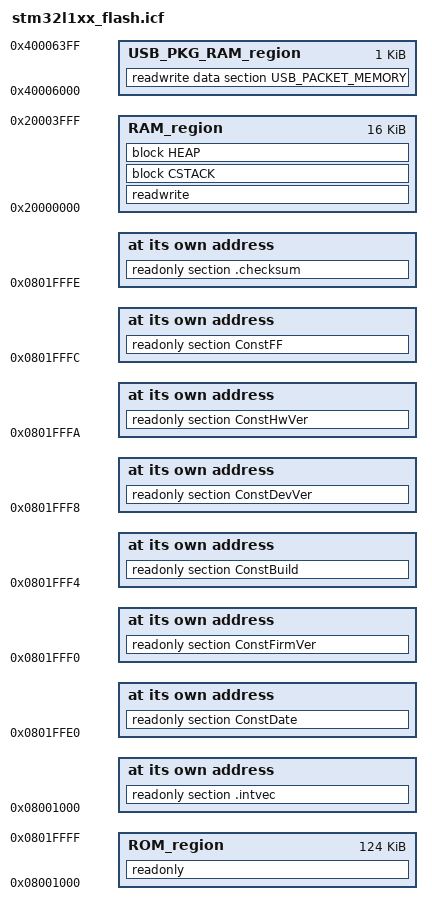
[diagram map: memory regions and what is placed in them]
/*###ICF### Section handled by ICF editor, don't touch! ****/
/*-Editor annotation file-*/
/* IcfEditorFile="$TOOLKIT_DIR$\config\ide\IcfEditor\cortex_v1_0.xml" */
/*-Specials-*/
define symbol __ICFEDIT_intvec_start__ = 0x08001000;
define symbol CHECKSUM                 = 0x0801FFFE;
define symbol __CONST_DATE             = 0x0801FFE0;
define symbol __CONST_FIRM_VER         = 0x0801FFF0;
define symbol __CONST_BUILD            = 0x0801FFF4;
define symbol __CONST_DEV_VER          = 0x0801FFF8;
define symbol __CONST_HW_VER           = 0x0801FFFA;
define symbol __CONST_FF               = 0x0801FFFC;

/*-Memory Regions-*/
define symbol __ICFEDIT_region_ROM_start__ = 0x08001000;
define symbol __ICFEDIT_region_ROM_end__   = 0x0801FFFF;
define symbol __ICFEDIT_region_RAM_start__ = 0x20000000;
define symbol __ICFEDIT_region_RAM_end__   = 0x20003FFF;
/*-Sizes-*/
define symbol __ICFEDIT_size_cstack__ = 0x250;
define symbol __ICFEDIT_size_heap__   = 0x0;
/**** End of ICF editor section. ###ICF###*/

define memory mem with size = 4G;
define region ROM_region   = mem:[from __ICFEDIT_region_ROM_start__   to __ICFEDIT_region_ROM_end__];
define region RAM_region   = mem:[from __ICFEDIT_region_RAM_start__   to __ICFEDIT_region_RAM_end__];

define symbol __region_USB_PKG_RAM_start__  = 0x40006000;
define symbol __region_USB_PKG_RAM_end__    = 0x400063FF;
define region USB_PKG_RAM_region = mem:[from __region_USB_PKG_RAM_start__ to __region_USB_PKG_RAM_end__];

define block CSTACK    with alignment = 8, size = __ICFEDIT_size_cstack__   { };
define block HEAP      with alignment = 8, size = __ICFEDIT_size_heap__     { };

initialize by copy { readwrite };
do not initialize  { section .noinit };

place at address mem:__ICFEDIT_intvec_start__ { readonly section .intvec };
place at address mem: CHECKSUM   { readonly section .checksum };
place at address mem: __CONST_DATE   { readonly section ConstDate };
place at address mem: __CONST_FIRM_VER   { readonly section ConstFirmVer };
place at address mem: __CONST_BUILD   { readonly section ConstBuild };
place at address mem: __CONST_DEV_VER   { readonly section ConstDevVer };
place at address mem: __CONST_HW_VER   { readonly section ConstHwVer };
place at address mem: __CONST_FF   { readonly section ConstFF };

place in ROM_region   { readonly };
place in RAM_region   { readwrite,
                        block CSTACK, block HEAP };
place in USB_PKG_RAM_region
                      { readwrite data section USB_PACKET_MEMORY  };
